VERSION "HIPBNYYYYYYYYYYYYYYYYYYYYYYYYYYYNNNNNNNNNN/4/%%%/4/'%**4NNN///"

NS_ :

BS_:

BU_: TestNode

BO_ 102 MsgDiscrete: 1 Vector__XXX
 SG_ Discrete : 0|3@1+ (1,0) [0|0] "" Vector__XXX

BO_ 101 MsgLine: 3 Vector__XXX
 SG_ Line : 0|10@1+ (1,0) [0|0] "" Vector__XXX

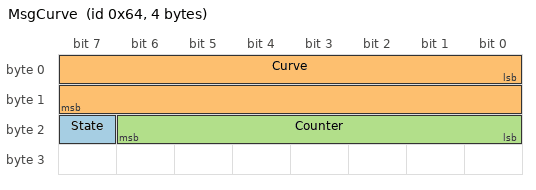
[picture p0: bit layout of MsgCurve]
BO_ 100 MsgCurve: 4 Vector__XXX
 SG_ State : 23|1@1+ (1,0) [0|1] "" Vector__XXX
 SG_ Curve : 0|16@1+ (0.1,0) [0|6500] "" Vector__XXX
 SG_ Counter : 16|7@1+ (1,0) [0|0] "" Vector__XXX

BO_ 17 MsgSine: 8 TestNode
 SG_ SineJitter : 16|16@1+ (0.0001,-1) [-1|1] "Volts" Vector__XXX
 SG_ Sine : 0|16@1+ (0.0001,-1) [-1|1] "Volts" Vector__XXX

BO_ 16 MsgSparse: 8 TestNode
 SG_ Sine : 0|16@1+ (0.0001,-1) [-1|1] "Volts" Vector__XXX

BO_ 18 MsgPeak: 4 TestNode
 SG_ Peak2 : 8|8@1+ (1,0) [0|255] "" Vector__XXX
 SG_ Peak1 : 0|8@1+ (1,0) [0|255] "" Vector__XXX
